# ATA5835 device description
Architecture: AVR8; Family: megaAVR
Registers are 8-bit, access not given, no defined reset value unless marked. A register's access mark holds for its fields unless they carry their own. Offsets are from the block's base; [hi:lo] are bit positions; {n}, {i} and the like mark numbered series; 'fields as' and 'values as' point back to an identical list.

## FREQS
Instances: FREQS 0x00
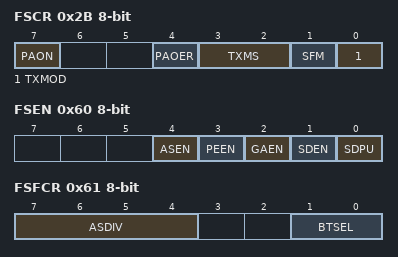
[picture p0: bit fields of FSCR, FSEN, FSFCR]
0x2B FSCR — Frequency Synthesizer Control Register
  [7] PAON — Power Amplifier Output is On
  [4] PAOER — Power Amplifier Output Enable Register
  [3:2] TXMS — Tx Modulation Source
    0=TXMOD_REGISTER; 1=TMDI_INPUT; 2=TX_MODULATOR_SERIAL_OUT
  [1] SFM — Select FSK Modulation
  [0] TXMOD — Tx Modulation
0x60 FSEN — Frequency Synthesizer Enable
  [4] ASEN — ASK Shaping Enable
  [3] PEEN — Pre-emphasis Filtering Enable
  [2] GAEN — Gauss Filtering Enable
  [1] SDEN — Sigma-delta Modulator Enable
  [0] SDPU — Sigma-delta Modulator Power Up
0x61 FSFCR — Frequency Synthesizer Filter Control Register
  [7:4] ASDIV — ASK Shaping Divider
  [1:0] BTSEL — Gauss Filter BT Selection
    0=BT_2; 1=BT_1_5; 2=BT_1; 3=BT_0_5
0x62 GACDIV 16-bit bits used 12:0 — Gauss Clock Divider
0x64 FFREQ1L — Fractional Frequency 1 Low Byte
0x65 FFREQ1M — Fractional Frequency 1 Middle Byte
0x66 FFREQ1H bits used 1:0 — Fractional Frequency 1 High Byte
0x67 FFREQ2L — Fractional Frequency 2 Low Byte
0x68 FFREQ2M — Fractional Frequency 2 Middle Byte
0x69 FFREQ2H bits used 1:0 — Fractional Frequency 2 High Byte

## FRSYNC
Instances: FRSYNC 0x00
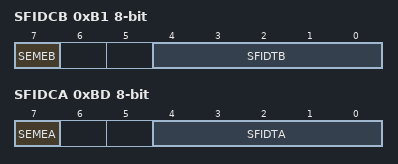
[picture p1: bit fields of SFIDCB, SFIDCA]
0xB1 SFIDCB — Start Frame ID Configuration Path B
  [7] SEMEB — Serial Mode Enable Path B
  [4:0] SFIDTB — Start Frame ID Threshold Path B
0xB2 SFIDLB bits used 5:0 — Start Frame ID Length Path B
0xB3 WUPTB bits used 4:0 — Wake-Up Pattern Threshold Path B
0xB4 WUPLB bits used 5:0 — Wake-Up Pattern Length Path B
{0xB4+i} SFID{i}B (i=1..4) — Start Frame ID Byte {i} Path B
{0xB8+i} WUP{i}B (i=1..4) — Wake-Up Pattern Byte {i} Path B
0xBD SFIDCA — Start Frame ID Configuration Path A
  [7] SEMEA — Serial Mode Enable Path A
  [4:0] SFIDTA — Start Frame ID Threshold Path A
0xBE SFIDLA bits used 5:0 — Start Frame ID Length Path A
0xBF WUPTA bits used 4:0 — Wake-Up Pattern Threshold Path A
0xC0 WUPLA bits used 5:0 — Wake-Up Pattern Length Path A
{0xC0+i} SFID{i}A (i=1..4) — Start Frame ID Byte {i} Path A
{0xC4+i} WUP{i}A (i=1..4) — Wake-Up Pattern Byte {i} Path A

## GPIOREGS
Instances: GPIOREGS 0x00
0x3A GPIOR0 — General Purpose I/O Register 0
{0x38+i} GPIOR{i} (i=3..6) — General Purpose I/O Register {i}
0x44 GPIOR1 — General Purpose I/O Register 1
0x45 GPIOR2 — General Purpose I/O Register 2

## IDCHK
Instances: IDCHK 0x00
{0x156+i} IDB{i} (i=0..3) — ID Check Byte {i}
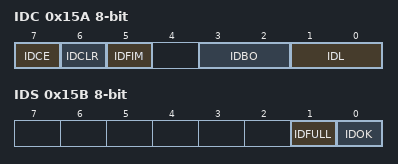
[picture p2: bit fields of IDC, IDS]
0x15A IDC — ID Check Configuration
  [7] IDCE — ID Check Execute
  [6] IDCLR — ID Clear
  [5] IDFIM — ID Full Interrupt Mask
  [3:2] IDBO — ID Byte Offset
  [1:0] IDL — ID Length
0x15B IDS — ID Check Status
  [1] IDFULL — ID Full Flag
  [0] IDOK — ID Check Ok Flag

## INT
Instances: INT 0x00
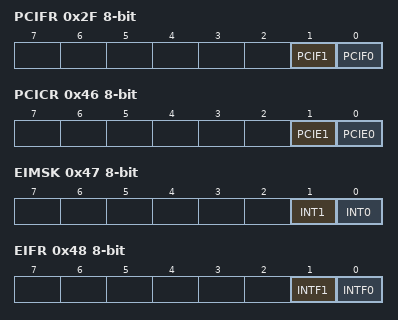
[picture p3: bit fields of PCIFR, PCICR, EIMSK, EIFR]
0x2F PCIFR — Pin Change Interrupt Flag Register
  [1] PCIF1 — Pin Change Interrupt Flag 1
  [0] PCIF0 — Pin Change Interrupt Flag 0
0x46 PCICR — Pin Change Interrupt Control Register
  [1] PCIE1 — Pin Change Interrupt Enable 1
  [0] PCIE0 — Pin Change Interrupt Enable 0
0x47 EIMSK — External Interrupt Mask
  [1] INT1 — External Interrupt Request 1 Enable
  [0] INT0 — External Interrupt Request 0 Enable
0x48 EIFR — External Interrupt Flag Register
  [1] INTF1 — External Interrupt Flag 1
  [0] INTF0 — External Interrupt Flag 0
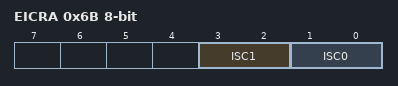
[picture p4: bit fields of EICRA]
0x6B EICRA — External Interrupt Control Register A
  [3:2] ISC1 — Interrupt Sense Control 1
    0=LOW_LEVEL_OF_INTX; 1=LOGICAL_CHANGE_OF_INTX; 2=FALLING_EDGE_OF_INTX; 3=RISING_EDGE_OF_INTX
  [1:0] ISC0 — Interrupt Sense Control 0
    values as ISC1
0x6C PCMSK0 — Pin Change Mask Register 0
  [7:0] PCINT — Pin Change Enable Mask
0x6D PCMSK1 — Pin Change Mask Register 1
  [5:0] PCINT (bit 8 of the value upward) — Pin Change Enable Mask
